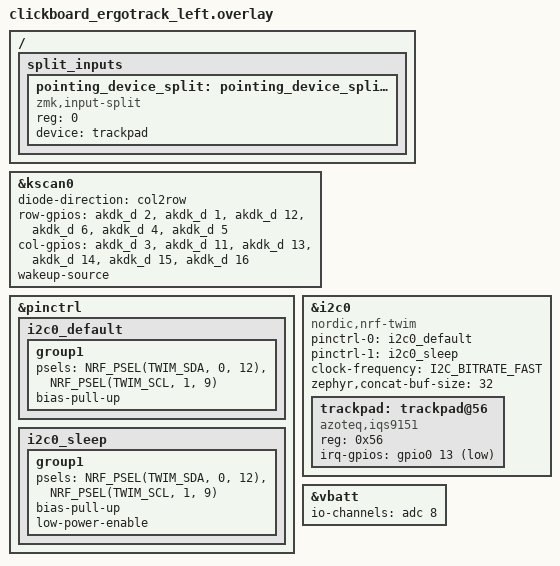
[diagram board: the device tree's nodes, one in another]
#include "clickboard_ergotrack.dtsi"

#include <dt-bindings/pinctrl/nrf-pinctrl.h>

#include <zephyr/dt-bindings/input/input-event-codes.h>

/ {
    split_inputs {
        #address-cells = <1>;
        #size-cells = <0>;

        pointing_device_split: pointing_device_split@0 {
            compatible = "zmk,input-split";
            reg = <0>;
            device = <&trackpad>;
        };
    };
};

&kscan0 {
    diode-direction = "col2row";
    row-gpios = <&akdk_d 2 (GPIO_ACTIVE_HIGH | GPIO_PULL_DOWN)>,
        <&akdk_d 1 (GPIO_ACTIVE_HIGH | GPIO_PULL_DOWN)>,
        <&akdk_d 12 (GPIO_ACTIVE_HIGH | GPIO_PULL_DOWN)>,
        <&akdk_d 6 (GPIO_ACTIVE_HIGH | GPIO_PULL_DOWN)>,
        <&akdk_d 4 (GPIO_ACTIVE_HIGH | GPIO_PULL_DOWN)>,
        <&akdk_d 5 (GPIO_ACTIVE_HIGH | GPIO_PULL_DOWN)>;
    col-gpios = <&akdk_d 3 (GPIO_ACTIVE_HIGH)>,
        <&akdk_d 11 (GPIO_ACTIVE_HIGH)>,
        <&akdk_d 13 (GPIO_ACTIVE_HIGH)>,
        <&akdk_d 14 (GPIO_ACTIVE_HIGH)>,
        <&akdk_d 15 (GPIO_ACTIVE_HIGH)>,
        <&akdk_d 16 (GPIO_ACTIVE_HIGH)>;
    wakeup-source;
};

&pinctrl {
    i2c0_default: i2c0_default {
        group1 {
            psels = <NRF_PSEL(TWIM_SDA, 0, 12)>,
                    <NRF_PSEL(TWIM_SCL, 1, 9)>;
            bias-pull-up;
        };
    };

    i2c0_sleep: i2c0_sleep {
        group1 {
            psels = <NRF_PSEL(TWIM_SDA, 0, 12)>,
                    <NRF_PSEL(TWIM_SCL, 1, 9)>;
            bias-pull-up;
            low-power-enable;
        };
    };
};

&i2c0 {
    status = "okay";
    compatible = "nordic,nrf-twim";
    pinctrl-0 = <&i2c0_default>;
    pinctrl-1 = <&i2c0_sleep>;
    pinctrl-names = "default", "sleep";
    clock-frequency = <I2C_BITRATE_FAST>;
    zephyr,concat-buf-size = <32>;

    trackpad: trackpad@56 {
        status = "okay";
        compatible = "azoteq,iqs9151";
        reg = <0x56>;
        irq-gpios = <&gpio0 13 (GPIO_ACTIVE_LOW | GPIO_PULL_UP)>; 
    };
};

/* 電池の測定先を VDD(電源ライン)に変える。
 *
 * ボードは `io-channels = <&adc 2>` = AIN2 = P0.04 を指していたが、P0.04 は
 * このボード定義のどこにも現れず、実測もそれを裏づけていた: 新品のCR2032で
 * ずっと1%、USBを挿して電源が3.3V付近にあるときですら0%。何も繋がっていない
 * ピンを読んでいたということ。
 *
 * モジュールは io-channels の数値を `NRF_SAADC_AIN0 + n` として入力の選択に
 * しか使わない。nRF52840 の PSELP は AIN0=1..AIN7=8, VDD=9 なので、
 * n=8 で VDD が選ばれる。CR2032 が電源に直結なら VDD の電圧 = 電池の電圧で、
 * 追加の配線も分圧抵抗も要らない。MIN=2000/MAX=3000 もそのまま
 * CR2032 の目盛りとして正しくなる。
 *
 * 制約: USB給電中は VDD がレギュレータから来るので、電池の状態に関係なく
 * 100%付近を指す。電池の残量として意味があるのは電池駆動のときだけ。
 * (裏返せば、USBを挿して100%に飛べば「電源を測れている」証拠になる)
 */
&vbatt {
    io-channels = <&adc 8>;
};
